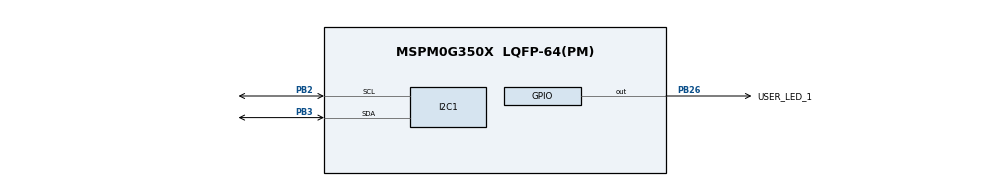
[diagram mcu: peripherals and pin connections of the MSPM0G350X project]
// @cliArgs --device "MSPM0G350X" --package "LQFP-64(PM)" --part "Default"
// @cliArgs --board /ti/boards/LP_MSPM0G3507 --rtos nortos

/**
 * Import the modules used in this configuration.
 */
const GPIO   = scripting.addModule("/ti/driverlib/GPIO", {}, false);
const GPIO1  = GPIO.addInstance();
const I2C    = scripting.addModule("/ti/driverlib/I2C", {}, false);
const I2C1   = I2C.addInstance();
const SYSCTL = scripting.addModule("/ti/driverlib/SYSCTL");

/**
 * Write custom configuration values to the imported modules.
 */
GPIO1.$name                          = "GPIO_LEDS";
GPIO1.associatedPins[0].$name        = "USER_LED_1";
GPIO1.associatedPins[0].assignedPort = "PORTB";
GPIO1.associatedPins[0].assignedPin  = "26";
GPIO1.associatedPins[0].pin.$assign  = "PB26";

const Board = scripting.addModule("/ti/driverlib/Board", {}, false);
Board.configureUnused = true;

I2C1.basicControllerBusSpeed   = 400000;
I2C1.advControllerTXFIFOTRIG   = "BYTES_1";
I2C1.basicTargetAddress        = 0x48;
I2C1.$name                     = "I2C";
I2C1.basicEnableTarget         = true;
I2C1.advTargetTXFIFOTRIG       = "BYTES_1";
I2C1.intTarget                 = ["RXFIFO_TRIGGER","START","STOP"];
I2C1.advAnalogGlitchFilter     = "DISABLED";
I2C1.advTargetTXEmptyEn        = true;
I2C1.peripheral.$assign        = "I2C1";
I2C1.peripheral.sdaPin.$assign = "PB3";
I2C1.peripheral.sclPin.$assign = "PB2";

SYSCTL.powerPolicy = "STOP0";
SYSCTL.forceDefaultClkConfig = true;
SYSCTL.clockTreeEn  = true;
